# uart_model: IP-XACT component
VLNV IcronTechnologies:IcronTechnologies:uart_model:1.0

## Parameters
addr_width = 8
bus_width = 32

## Bus interfaces (logical=physical port)
default_map: slave AGNISYS:AGNISYS:APB:1.0, memory map uartmap
  pclk=pclk, presetn=presetn, psel=psel, penable=penable, pwrite=pwrite, pprot=pprot, pstrb=pstrb, pwdata=pwdata, paddr=paddr, pready=pready, prdata=prdata, pslverr=pslverr

## Ports
in pclk
in presetn
in psel
in penable
in pwrite
in pprot[2:0]
in pstrb[(bus_width div 8 )-1:0]
in pwdata[bus_width -1:0]
in paddr[addr_width -1:0]
out pready
out prdata[bus_width -1:0]
out pslverr
out uart_regsversion_major_r[7:0]
out uart_regsversion_minor_r[7:0]
out uart_regsversion_patch_r[7:0]
out uart_regstx_fifo_enb
out uart_regstx_fifo_fifo_clear_r
out uart_regsregtx_fifo_fifo_clear_wr_pulse
in uart_regstx_fifo_fifo_af_in
in uart_regstx_fifo_fifo_af_in_enb
in uart_regstx_fifo_fifo_ae_in
in uart_regstx_fifo_fifo_ae_in_enb
in uart_regstx_fifo_fifo_full_in
in uart_regstx_fifo_fifo_full_in_enb
in uart_regstx_fifo_fifo_empty_in
in uart_regstx_fifo_fifo_empty_in_enb
out uart_regstx_fifo_fifo_aft_r[7:0]
out uart_regstx_fifo_fifo_aet_r[7:0]
in uart_regstx_fifo_fifo_depth_in[7:0]
in uart_regstx_fifo_fifo_depth_in_enb
out uart_regsrx_fifo_enb
out uart_regsrx_fifo_fifo_clear_r
out uart_regsregrx_fifo_fifo_clear_wr_pulse
in uart_regsrx_fifo_fifo_af_in
in uart_regsrx_fifo_fifo_af_in_enb
in uart_regsrx_fifo_fifo_ae_in
in uart_regsrx_fifo_fifo_ae_in_enb
in uart_regsrx_fifo_fifo_full_in
in uart_regsrx_fifo_fifo_full_in_enb
in uart_regsrx_fifo_fifo_empty_in
in uart_regsrx_fifo_fifo_empty_in_enb
out uart_regsrx_fifo_fifo_aft_r[7:0]
out uart_regsrx_fifo_fifo_aet_r[7:0]
in uart_regsrx_fifo_fifo_depth_in[7:0]
in uart_regsrx_fifo_fifo_depth_in_enb
out uart_regstx_data_enb
out uart_regstx_data_val_r[7:0]
out uart_regsregtx_data_val_wr_pulse
in uart_regsrx_data_val_in[7:0]
in uart_regsrx_data_val_in_enb
out uart_regsrx_data_val_rd_pulse
out uart_regscontrol_enb
out uart_regscontrol_prescaler_r[15:0]
out uart_regscontrol_tx_irq_en_r
out uart_regscontrol_rx_irq_en_r
out uart_regscontrol_tx_en_r
out uart_regscontrol_rx_en_r
out uart_regstimeout_enb
out uart_regstimeout_val_r[31:0]
in uart_regserrors_overrun_err_in
in uart_regserrors_overrun_err_in_enb
in uart_regserrors_stop_err_in
in uart_regserrors_stop_err_in_enb
in uart_regserrors_start_err_in
in uart_regserrors_start_err_in_enb

## Address spaces and blocks
uartmap.uart: base 0x000, range 0x100, width 32

## Registers
Registers are 32-bit, read-write, reset 0x0 unless marked. A register's access mark holds for its fields unless they carry their own. Offsets are from the block's base; lines under a group give offsets from that group; [hi:lo] are bit positions; {n}, {i} and the like mark numbered series; 'fields as' and 'values as' point back to an identical list; <NAME> marks a mode.

## uartmap.uart — FIFO-based UART
Base 0x00000000
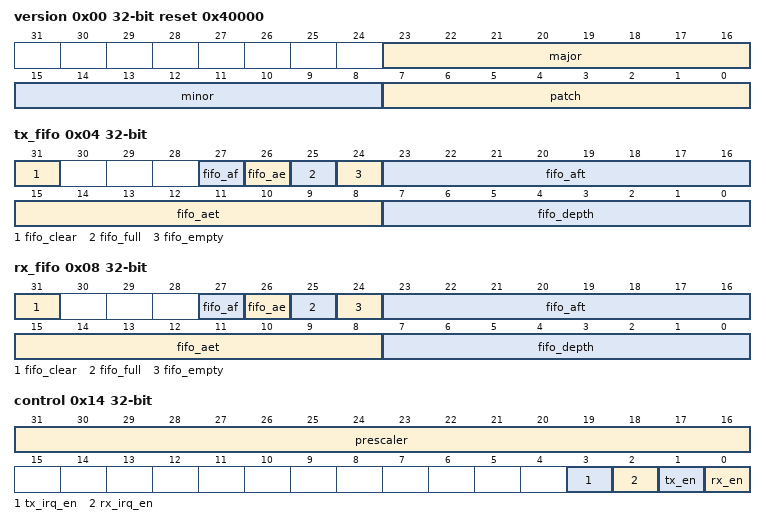
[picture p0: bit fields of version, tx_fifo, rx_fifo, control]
0x00 version ro reset 0x40000
  [23:16] major — Major version
  [15:8] minor — Minor version
  [7:0] patch — Patch version
0x04 tx_fifo access per field — TX FIFO control and status
  [31] fifo_clear rw
  [27] fifo_af ro — FIFO almost full status field. A 1 indicates an almost full or full FIFO. This bit is set when there are between fifo_aft and fifo_depth number of entries in the FIFO.
  [26] fifo_ae ro — FIFO almost empty status field. A 1 indicates an almost empty or empty FIFO. This bit is set when there are between 0 and fifo_aet number of entries in the FIFO.
  [25] fifo_full ro — FIFO full status field. A 1 indicates a full FIFO.
  [24] fifo_empty ro — FIFO empty status field. A 1 indicates an empty FIFO.
  [23:16] fifo_aft rw — FIFO almost full threshold
  [15:8] fifo_aet rw — FIFO almost empty threshold
  [7:0] fifo_depth ro — FIFO depth (always 1 byte wide)
0x08 rx_fifo access per field — RX FIFO control and status
  fields as tx_fifo
0x0C tx_data wo
  [7:0] val — Byte to write into the TX FIFO
0x10 rx_data ro
  [7:0] val — Byte to read from the RX FIFO
0x14 control
  [31:16] prescaler — Prescaler reload value round(module clock frequency / baud rate)
  [3] tx_irq_en — Transmitter interrupt enable
  [2] rx_irq_en — Receiver interrupt enable
  [1] tx_en — Transmitter enable
  [0] rx_en — Receiver enable
0x18 timeout
  [31:0] val — > 0: If no character was received within this number of module clock cycles and RX FIFO is not empty RX IRQ will be asserted. If a new character is received before timer expiry or when the timer is expired, the timer is reset and restarted. 0: Disables the timeout functionality
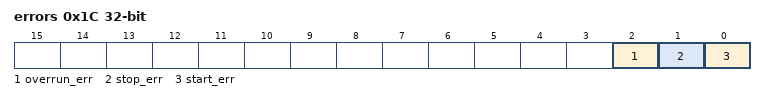
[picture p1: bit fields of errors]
0x1C errors — Errors - Write 1 to clear
  [2] overrun_err write-1-clears — Overrun Error: If this is 1 the RX FIFO was full and a received character had to be discarded
  [1] stop_err write-1-clears — Stop Error: If this is 1 a character was received but a 0 was seen in the middle of what was expected to be the stop bit; this condition does not impact how the received character is treated
  [0] start_err write-1-clears — Start Error: A falling edge on the UART RX line was detected but before reaching the middle of the start bit a 1 was seen; this condition does not impact how the received character is treated
